# bao1x register map
Vendor: baochip; File version: 1.0
Registers are 32-bit, read-write, reset 0x0 unless marked. A register's access mark holds for its fields unless they carry their own. Offsets are from the block's base; [hi:lo] are bit positions; {n}, {i} and the like mark numbered series.

## IRQARRAY14
Base 0xE000A000
0x00 EV_SOFT — Software interrupt trigger register. ) Bits set to `1` will trigger an interrupt. Interrupts trigger on write, but the value will persist in the register, allowing software to determine if a software interrupt was triggered by reading back the register. Software is responsible for clearing the register to 0. Repeated `1` writes without clearing will still trigger an interrupt.
  [15:0] trigger
0x04 EV_EDGE_TRIGGERED — If a bit is set to 1, then the hardware trigger is edge-triggered
  [15:0] use_edge
0x08 EV_POLARITY — If a bit is set to 1, then the polarity is rising edge triggered; 0 is falling edge triggered. Bit is ignored if `edge_triggered` is 0.
  [15:0] rising
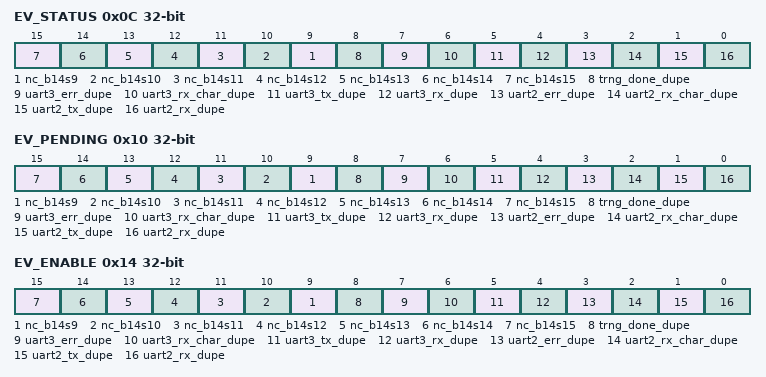
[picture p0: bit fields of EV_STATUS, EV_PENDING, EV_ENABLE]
0x0C EV_STATUS — `1` when a "nc_b14s15" event occurs. This event uses an `EventSourceFlex` form of triggering
  [n] nc_b14s{n} (n=9..15) — Level of the ``nc_b14s{n}`` event
  [8] trng_done_dupe — Level of the ``trng_done_dupe`` event
  [7] uart3_err_dupe — Level of the ``uart3_err_dupe`` event
  [6] uart3_rx_char_dupe — Level of the ``uart3_rx_char_dupe`` event
  [5] uart3_tx_dupe — Level of the ``uart3_tx_dupe`` event
  [4] uart3_rx_dupe — Level of the ``uart3_rx_dupe`` event
  [3] uart2_err_dupe — Level of the ``uart2_err_dupe`` event
  [2] uart2_rx_char_dupe — Level of the ``uart2_rx_char_dupe`` event
  [1] uart2_tx_dupe — Level of the ``uart2_tx_dupe`` event
  [0] uart2_rx_dupe — Level of the ``uart2_rx_dupe`` event
0x10 EV_PENDING — `1` when a "nc_b14s15" event occurs. This event uses an `EventSourceFlex` form of triggering
  [n] nc_b14s{n} (n=9..15) — `1` when a "nc_b14s{n}" event occurs. This event uses an `EventSourceFlex` form of triggering
  [8] trng_done_dupe — `1` when a "trng_done_dupe" event occurs. This event uses an `EventSourceFlex` form of triggering
  [7] uart3_err_dupe — `1` when a "uart3_err_dupe" event occurs. This event uses an `EventSourceFlex` form of triggering
  [6] uart3_rx_char_dupe — `1` when a "uart3_rx_char_dupe" event occurs. This event uses an `EventSourceFlex` form of triggering
  [5] uart3_tx_dupe — `1` when a "uart3_tx_dupe" event occurs. This event uses an `EventSourceFlex` form of triggering
  [4] uart3_rx_dupe — `1` when a "uart3_rx_dupe" event occurs. This event uses an `EventSourceFlex` form of triggering
  [3] uart2_err_dupe — `1` when a "uart2_err_dupe" event occurs. This event uses an `EventSourceFlex` form of triggering
  [2] uart2_rx_char_dupe — `1` when a "uart2_rx_char_dupe" event occurs. This event uses an `EventSourceFlex` form of triggering
  [1] uart2_tx_dupe — `1` when a "uart2_tx_dupe" event occurs. This event uses an `EventSourceFlex` form of triggering
  [0] uart2_rx_dupe — `1` when a "uart2_rx_dupe" event occurs. This event uses an `EventSourceFlex` form of triggering
0x14 EV_ENABLE — `1` when a "nc_b14s15" event occurs. This event uses an `EventSourceFlex` form of triggering
  [n] nc_b14s{n} (n=9..15) — Write a ``1`` to enable the ``nc_b14s{n}`` Event
  [8] trng_done_dupe — Write a ``1`` to enable the ``trng_done_dupe`` Event
  [7] uart3_err_dupe — Write a ``1`` to enable the ``uart3_err_dupe`` Event
  [6] uart3_rx_char_dupe — Write a ``1`` to enable the ``uart3_rx_char_dupe`` Event
  [5] uart3_tx_dupe — Write a ``1`` to enable the ``uart3_tx_dupe`` Event
  [4] uart3_rx_dupe — Write a ``1`` to enable the ``uart3_rx_dupe`` Event
  [3] uart2_err_dupe — Write a ``1`` to enable the ``uart2_err_dupe`` Event
  [2] uart2_rx_char_dupe — Write a ``1`` to enable the ``uart2_rx_char_dupe`` Event
  [1] uart2_tx_dupe — Write a ``1`` to enable the ``uart2_tx_dupe`` Event
  [0] uart2_rx_dupe — Write a ``1`` to enable the ``uart2_rx_dupe`` Event

## IRQARRAY15
Base 0xE000B000
0x00 EV_SOFT — Software interrupt trigger register. ) Bits set to `1` will trigger an interrupt. Interrupts trigger on write, but the value will persist in the register, allowing software to determine if a software interrupt was triggered by reading back the register. Software is responsible for clearing the register to 0. Repeated `1` writes without clearing will still trigger an interrupt.
  [15:0] trigger
0x04 EV_EDGE_TRIGGERED — If a bit is set to 1, then the hardware trigger is edge-triggered
  [15:0] use_edge
0x08 EV_POLARITY — If a bit is set to 1, then the polarity is rising edge triggered; 0 is falling edge triggered. Bit is ignored if `edge_triggered` is 0.
  [15:0] rising
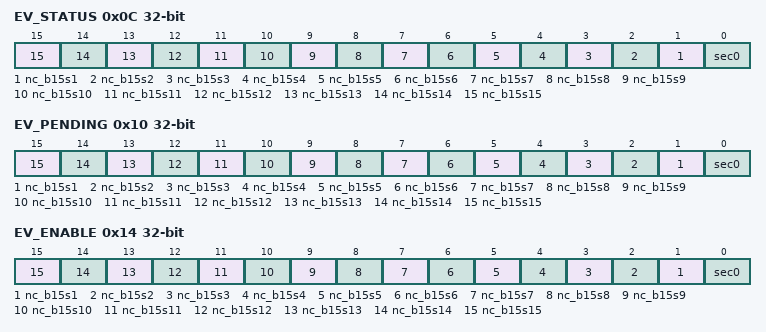
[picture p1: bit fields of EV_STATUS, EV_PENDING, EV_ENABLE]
0x0C EV_STATUS — `1` when a "nc_b15s15" event occurs. This event uses an `EventSourceFlex` form of triggering
  [n] nc_b15s{n} (n=1..15) — Level of the ``nc_b15s{n}`` event
  [0] sec0 — Level of the ``sec0`` event
0x10 EV_PENDING — `1` when a "nc_b15s15" event occurs. This event uses an `EventSourceFlex` form of triggering
  [n] nc_b15s{n} (n=1..15) — `1` when a "nc_b15s{n}" event occurs. This event uses an `EventSourceFlex` form of triggering
  [0] sec0 — `1` when a "sec0" event occurs. This event uses an `EventSourceFlex` form of triggering
0x14 EV_ENABLE — `1` when a "nc_b15s15" event occurs. This event uses an `EventSourceFlex` form of triggering
  [n] nc_b15s{n} (n=1..15) — Write a ``1`` to enable the ``nc_b15s{n}`` Event
  [0] sec0 — Write a ``1`` to enable the ``sec0`` Event
